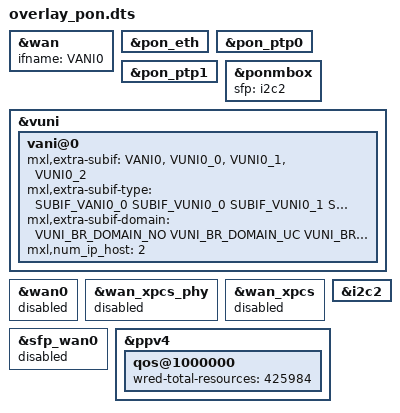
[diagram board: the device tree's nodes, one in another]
// SPDX-License-Identifier: GPL-2.0
/*
 * Copyright (C) 2024-2025 MaxLinear, Inc.
 */

/dts-v1/;
/plugin/;

#include <dt-bindings/net/mxl,vuni.h>
#include <dt-bindings/net/mxl,lgm-cqm.h>
#include <dt-bindings/soc/mxl,firewall.h>

#include "bm_main_pon.dtsi"

&wan {
	ifname = "VANI0";
};

&pon_eth {
	status = "okay";
};

&pon_ptp0 {
	status = "okay";
};

&pon_ptp1 {
	status = "okay";
};

&ponmbox {
	status = "okay";
	/* I2C bus to the optical WAN transceiver */
	sfp = <&i2c2>;
};

&vuni {
	status = "okay";
	vani@0 {
		mxl,extra-subif = "VANI0", "VUNI0_0", "VUNI0_1", "VUNI0_2";
		mxl,extra-subif-type = <SUBIF_VANI0_0 SUBIF_VUNI0_0 SUBIF_VUNI0_1 SUBIF_VUNI0_2>;
		mxl,extra-subif-domain = <VUNI_BR_DOMAIN_NO VUNI_BR_DOMAIN_UC VUNI_BR_DOMAIN_MC VUNI_BR_DOMAIN_BC>;
		mxl,num_ip_host = <2>;
	};
};

&wan0 {
	status = "disabled";
};

/* WAN XPCS PHY */
&wan_xpcs_phy {
	status = "disabled";
};

/* XPCS setting */
&wan_xpcs {
	status = "disabled";
};

&i2c2 {
	status = "okay";
};

#if !defined(CONFIG_OSP_TB341_v1_PON_OVERLAY)
&sfp_wan0 {
	status = "disabled";
};

&ppv4 {
	qos@1000000 {
		wred-total-resources = <425984>;
	};
};
#else
&hsiol_xpcs1 {
	status = "disabled";
};

&gpio2 {
	sfp_eth_tx_disable {
		status = "disabled";
	};
};

&cqm_lgm {
	intel,pon_wan_bm_cfg = "enabled";
};
#endif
